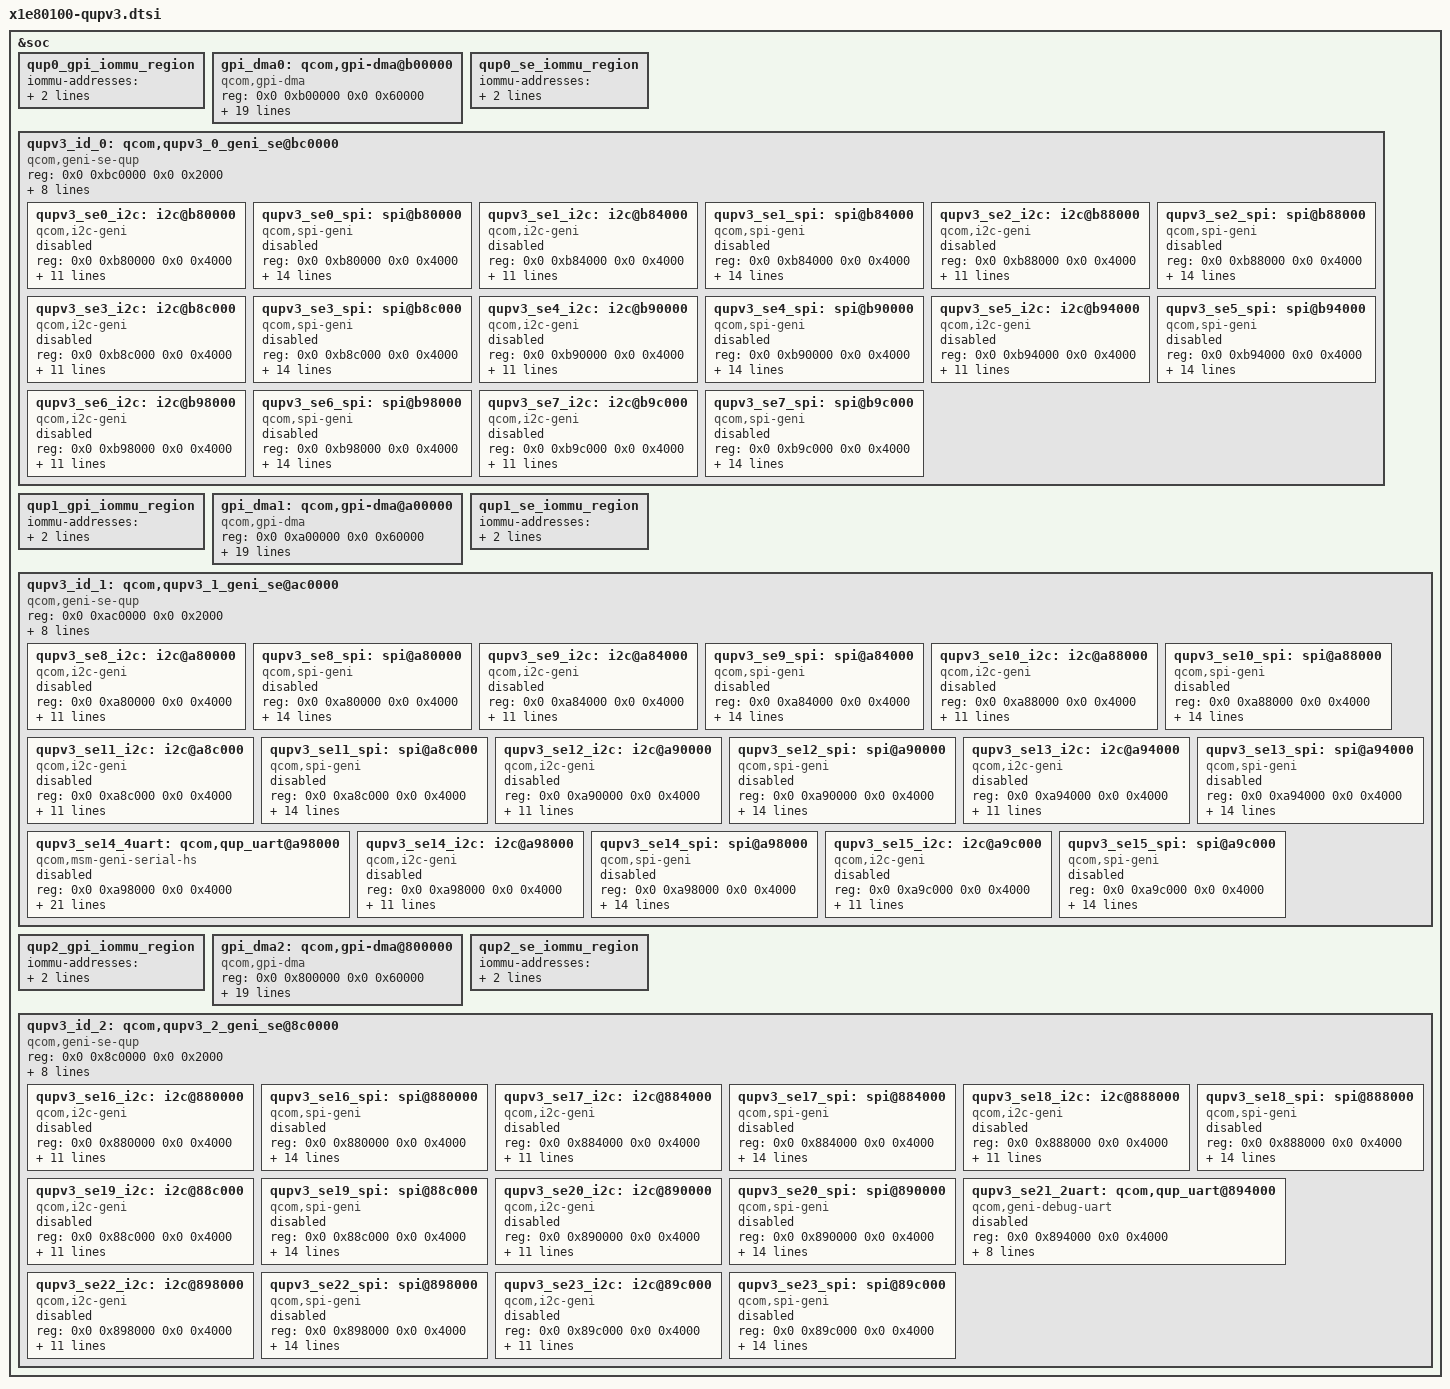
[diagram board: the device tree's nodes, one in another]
// SPDX-License-Identifier: BSD-3-Clause
/*
 * Copyright (c) Qualcomm Technologies, Inc. and/or its subsidiaries.
 */
#include <dt-bindings/clock/qcom,x1e80100-gcc.h>

&soc {
	qup0_gpi_iommu_region: qup0_gpi_iommu_region {
		iommu-addresses = <&gpi_dma0 0x0 0x0 0x0 0x100000>,
				  <&gpi_dma0 0x0 0x200000 0xffffffff 0xffe00000>;
	};

	gpi_dma0: qcom,gpi-dma@b00000 {
		compatible = "qcom,gpi-dma";
		#dma-cells = <5>;
		reg = <0x0 0xb00000 0x0 0x60000>;
		reg-names = "gpi-top";
		iommus = <&apps_smmu 0x0456 0x0>;
		qcom,max-num-gpii = <12>;
		interrupts = <GIC_SPI 588 IRQ_TYPE_LEVEL_HIGH>,
			     <GIC_SPI 589 IRQ_TYPE_LEVEL_HIGH>,
			     <GIC_SPI 590 IRQ_TYPE_LEVEL_HIGH>,
			     <GIC_SPI 591 IRQ_TYPE_LEVEL_HIGH>,
			     <GIC_SPI 592 IRQ_TYPE_LEVEL_HIGH>,
			     <GIC_SPI 593 IRQ_TYPE_LEVEL_HIGH>,
			     <GIC_SPI 594 IRQ_TYPE_LEVEL_HIGH>,
			     <GIC_SPI 595 IRQ_TYPE_LEVEL_HIGH>,
			     <GIC_SPI 596 IRQ_TYPE_LEVEL_HIGH>,
			     <GIC_SPI 597 IRQ_TYPE_LEVEL_HIGH>,
			     <GIC_SPI 598 IRQ_TYPE_LEVEL_HIGH>,
			     <GIC_SPI 599 IRQ_TYPE_LEVEL_HIGH>;
		qcom,gpii-mask = <0x3f>;
		qcom,ev-factor = <1>;
		memory-region = <&qup0_gpi_iommu_region>;
		qcom,gpi-ee-offset = <0x10000>;
		dma-coherent;
		status = "okay";
	};

	qup0_se_iommu_region: qup0_se_iommu_region {
		iommu-addresses = <&qupv3_id_0 0x0 0x0 0x0 0x40000000>,
				  <&qupv3_id_0 0x0 0x50000000 0xffffffff 0xb0000000>;
	};

	qupv3_id_0: qcom,qupv3_0_geni_se@bc0000 {
		compatible = "qcom,geni-se-qup";
		reg = <0x0 0xbc0000 0x0 0x2000>;
		clock-names = "m-ahb", "s-ahb";
		clocks = <&gcc GCC_QUPV3_WRAP_0_M_AHB_CLK>,
			 <&gcc GCC_QUPV3_WRAP_0_S_AHB_CLK>;
		iommus = <&apps_smmu 0x0443 0x0>;
		memory-region = <&qup0_se_iommu_region>;
		qcom,iommu-geometry = <0x0 0x40000000 0x0 0x10000000>;
		qcom,iommu-dma = "fastmap";
		dma-coherent;
		#address-cells = <2>;
		#size-cells = <2>;
		ranges;
		status = "okay";

		qupv3_se0_i2c: i2c@b80000 {
			compatible = "qcom,i2c-geni";
			reg = <0x0 0xb80000 0x0 0x4000>;
			interrupts = <GIC_SPI 373 IRQ_TYPE_LEVEL_HIGH>;
			clock-names = "se-clk";
			clocks = <&gcc GCC_QUPV3_WRAP0_S0_CLK>;
			interconnect-names = "qup-core", "qup-config", "qup-memory";
			interconnects = <&clk_virt MASTER_QUP_CORE_0 &clk_virt SLAVE_QUP_CORE_0>,
					<&gem_noc MASTER_APPSS_PROC &config_noc SLAVE_QUP_0>,
					<&aggre1_noc MASTER_QUP_0 &mc_virt SLAVE_EBI1>;
			pinctrl-names = "default", "sleep";
			pinctrl-0 = <&qupv3_se0_i2c_sda_active>, <&qupv3_se0_i2c_scl_active>;
			pinctrl-1 = <&qupv3_se0_i2c_sleep>;
			dmas = <&gpi_dma0 0 0 3 64 0>,
			       <&gpi_dma0 1 0 3 64 0>;
			dma-names = "tx", "rx";
			status = "disabled";
		};

		qupv3_se0_spi: spi@b80000 {
			compatible = "qcom,spi-geni";
			reg = <0x0 0xb80000 0x0 0x4000>;
			reg-names = "se_phys";
			interrupts = <GIC_SPI 373 IRQ_TYPE_LEVEL_HIGH>;
			clock-names = "se-clk";
			clocks = <&gcc GCC_QUPV3_WRAP0_S0_CLK>;
			interconnect-names = "qup-core", "qup-config", "qup-memory";
			interconnects = <&clk_virt MASTER_QUP_CORE_0 &clk_virt SLAVE_QUP_CORE_0>,
					<&gem_noc MASTER_APPSS_PROC &config_noc SLAVE_QUP_0>,
					<&aggre1_noc MASTER_QUP_0 &mc_virt SLAVE_EBI1>;
			pinctrl-names = "default", "sleep";
			pinctrl-0 = <&qupv3_se0_spi_mosi_active>, <&qupv3_se0_spi_miso_active>,
				    <&qupv3_se0_spi_clk_active>, <&qupv3_se0_spi_cs_active>;
			pinctrl-1 = <&qupv3_se0_spi_sleep>;
			dmas = <&gpi_dma0 0 0 1 64 0>,
				<&gpi_dma0 1 0 1 64 0>;
			dma-names = "tx", "rx";
			spi-max-frequency = <50000000>;
			status = "disabled";
		};

		qupv3_se1_i2c: i2c@b84000 {
			compatible = "qcom,i2c-geni";
			reg = <0x0 0xb84000 0x0 0x4000>;
			interrupts = <GIC_SPI 583 IRQ_TYPE_LEVEL_HIGH>;
			clock-names = "se-clk";
			clocks = <&gcc GCC_QUPV3_WRAP0_S1_CLK>;
			interconnect-names = "qup-core", "qup-config", "qup-memory";
			interconnects = <&clk_virt MASTER_QUP_CORE_0 &clk_virt SLAVE_QUP_CORE_0>,
					<&gem_noc MASTER_APPSS_PROC &config_noc SLAVE_QUP_0>,
					<&aggre1_noc MASTER_QUP_0 &mc_virt SLAVE_EBI1>;
			pinctrl-names = "default", "sleep";
			pinctrl-0 = <&qupv3_se1_i2c_sda_active>, <&qupv3_se1_i2c_scl_active>;
			pinctrl-1 = <&qupv3_se1_i2c_sleep>;
			dmas = <&gpi_dma0 0 1 3 64 0>,
			       <&gpi_dma0 1 1 3 64 0>;
			dma-names = "tx", "rx";
			status = "disabled";
		};

		qupv3_se1_spi: spi@b84000 {
			compatible = "qcom,spi-geni";
			reg = <0x0 0xb84000 0x0 0x4000>;
			reg-names = "se_phys";
			interrupts = <GIC_SPI 583 IRQ_TYPE_LEVEL_HIGH>;
			clock-names = "se-clk";
			clocks = <&gcc GCC_QUPV3_WRAP0_S1_CLK>;
			interconnect-names = "qup-core", "qup-config", "qup-memory";
			interconnects = <&clk_virt MASTER_QUP_CORE_0 &clk_virt SLAVE_QUP_CORE_0>,
					<&gem_noc MASTER_APPSS_PROC &config_noc SLAVE_QUP_0>,
					<&aggre1_noc MASTER_QUP_0 &mc_virt SLAVE_EBI1>;
			pinctrl-names = "default", "sleep";
			pinctrl-0 = <&qupv3_se1_spi_mosi_active>, <&qupv3_se1_spi_miso_active>,
				    <&qupv3_se1_spi_clk_active>, <&qupv3_se1_spi_cs_active>;
			pinctrl-1 = <&qupv3_se1_spi_sleep>;
			dmas = <&gpi_dma0 0 1 1 64 0>,
			       <&gpi_dma0 1 1 1 64 0>;
			dma-names = "tx", "rx";
			spi-max-frequency = <50000000>;
			status = "disabled";
		};

		qupv3_se2_i2c: i2c@b88000 {
			compatible = "qcom,i2c-geni";
			reg = <0x0 0xb88000 0x0 0x4000>;
			interrupts = <GIC_SPI 584 IRQ_TYPE_LEVEL_HIGH>;
			clock-names = "se-clk";
			clocks = <&gcc GCC_QUPV3_WRAP0_S2_CLK>;
			interconnect-names = "qup-core", "qup-config", "qup-memory";
			interconnects = <&clk_virt MASTER_QUP_CORE_0 &clk_virt SLAVE_QUP_CORE_0>,
					<&gem_noc MASTER_APPSS_PROC &config_noc SLAVE_QUP_0>,
					<&aggre1_noc MASTER_QUP_0 &mc_virt SLAVE_EBI1>;
			pinctrl-names = "default", "sleep";
			pinctrl-0 = <&qupv3_se2_i2c_sda_active>, <&qupv3_se2_i2c_scl_active>;
			pinctrl-1 = <&qupv3_se2_i2c_sleep>;
			dmas = <&gpi_dma0 0 2 3 64 0>,
			       <&gpi_dma0 1 2 3 64 0>;
			dma-names = "tx", "rx";
			status = "disabled";
		};

		qupv3_se2_spi: spi@b88000 {
			compatible = "qcom,spi-geni";
			reg = <0x0 0xb88000 0x0 0x4000>;
			reg-names = "se_phys";
			interrupts = <GIC_SPI 584 IRQ_TYPE_LEVEL_HIGH>;
			clock-names = "se-clk";
			clocks = <&gcc GCC_QUPV3_WRAP0_S2_CLK>;
			interconnect-names = "qup-core", "qup-config", "qup-memory";
			interconnects = <&clk_virt MASTER_QUP_CORE_0 &clk_virt SLAVE_QUP_CORE_0>,
					<&gem_noc MASTER_APPSS_PROC &config_noc SLAVE_QUP_0>,
					<&aggre1_noc MASTER_QUP_0 &mc_virt SLAVE_EBI1>;
			pinctrl-names = "default", "sleep";
			pinctrl-0 = <&qupv3_se2_spi_mosi_active>, <&qupv3_se2_spi_miso_active>,
				    <&qupv3_se2_spi_clk_active>, <&qupv3_se2_spi_cs_active>;
			pinctrl-1 = <&qupv3_se2_spi_sleep>;
			dmas = <&gpi_dma0 0 2 1 64 0>,
			       <&gpi_dma0 1 2 1 64 0>;
			dma-names = "tx", "rx";
			spi-max-frequency = <50000000>;
			status = "disabled";
		};

		qupv3_se3_i2c: i2c@b8c000 {
			compatible = "qcom,i2c-geni";
			reg = <0x0 0xb8c000 0x0 0x4000>;
			interrupts = <GIC_SPI 585 IRQ_TYPE_LEVEL_HIGH>;
			clock-names = "se-clk";
			clocks = <&gcc GCC_QUPV3_WRAP0_S3_CLK>;
			interconnect-names = "qup-core", "qup-config", "qup-memory";
			interconnects = <&clk_virt MASTER_QUP_CORE_0 &clk_virt SLAVE_QUP_CORE_0>,
					<&gem_noc MASTER_APPSS_PROC &config_noc SLAVE_QUP_0>,
					<&aggre1_noc MASTER_QUP_0 &mc_virt SLAVE_EBI1>;
			pinctrl-names = "default", "sleep";
			pinctrl-0 = <&qupv3_se3_i2c_sda_active>, <&qupv3_se3_i2c_scl_active>;
			pinctrl-1 = <&qupv3_se3_i2c_sleep>;
			dmas = <&gpi_dma0 0 3 3 64 0>,
			       <&gpi_dma0 1 3 3 64 0>;
			dma-names = "tx", "rx";
			status = "disabled";
		};

		qupv3_se3_spi: spi@b8c000 {
			compatible = "qcom,spi-geni";
			reg = <0x0 0xb8c000 0x0 0x4000>;
			reg-names = "se_phys";
			interrupts = <GIC_SPI 585 IRQ_TYPE_LEVEL_HIGH>;
			clock-names = "se-clk";
			clocks = <&gcc GCC_QUPV3_WRAP0_S3_CLK>;
			interconnect-names = "qup-core", "qup-config", "qup-memory";
			interconnects = <&clk_virt MASTER_QUP_CORE_0 &clk_virt SLAVE_QUP_CORE_0>,
					<&gem_noc MASTER_APPSS_PROC &config_noc SLAVE_QUP_0>,
					<&aggre1_noc MASTER_QUP_0 &mc_virt SLAVE_EBI1>;
			pinctrl-names = "default", "sleep";
			pinctrl-0 = <&qupv3_se3_spi_mosi_active>, <&qupv3_se3_spi_miso_active>,
				    <&qupv3_se3_spi_clk_active>, <&qupv3_se3_spi_cs_active>;
			pinctrl-1 = <&qupv3_se3_spi_sleep>;
			dmas = <&gpi_dma0 0 3 1 64 0>,
			       <&gpi_dma0 1 3 1 64 0>;
			dma-names = "tx", "rx";
			spi-max-frequency = <50000000>;
			status = "disabled";
		};

		qupv3_se4_i2c: i2c@b90000 {
			compatible = "qcom,i2c-geni";
			reg = <0x0 0xb90000 0x0 0x4000>;
			interrupts = <GIC_SPI 586 IRQ_TYPE_LEVEL_HIGH>;
			clock-names = "se-clk";
			clocks = <&gcc GCC_QUPV3_WRAP0_S4_CLK>;
			interconnect-names = "qup-core", "qup-config", "qup-memory";
			interconnects = <&clk_virt MASTER_QUP_CORE_0 &clk_virt SLAVE_QUP_CORE_0>,
					<&gem_noc MASTER_APPSS_PROC &config_noc SLAVE_QUP_0>,
					<&aggre1_noc MASTER_QUP_0 &mc_virt SLAVE_EBI1>;
			pinctrl-names = "default", "sleep";
			pinctrl-0 = <&qupv3_se4_i2c_sda_active>, <&qupv3_se4_i2c_scl_active>;
			pinctrl-1 = <&qupv3_se4_i2c_sleep>;
			dmas = <&gpi_dma0 0 4 3 64 0>,
			       <&gpi_dma0 1 4 3 64 0>;
			dma-names = "tx", "rx";
			status = "disabled";
		};

		qupv3_se4_spi: spi@b90000 {
			compatible = "qcom,spi-geni";
			reg = <0x0 0xb90000 0x0 0x4000>;
			reg-names = "se_phys";
			interrupts = <GIC_SPI 586 IRQ_TYPE_LEVEL_HIGH>;
			clock-names = "se-clk";
			clocks = <&gcc GCC_QUPV3_WRAP0_S4_CLK>;
			interconnect-names = "qup-core", "qup-config", "qup-memory";
			interconnects = <&clk_virt MASTER_QUP_CORE_0 &clk_virt SLAVE_QUP_CORE_0>,
					<&gem_noc MASTER_APPSS_PROC &config_noc SLAVE_QUP_0>,
					<&aggre1_noc MASTER_QUP_0 &mc_virt SLAVE_EBI1>;
			pinctrl-names = "default", "sleep";
			pinctrl-0 = <&qupv3_se4_spi_mosi_active>, <&qupv3_se4_spi_miso_active>,
				    <&qupv3_se4_spi_clk_active>, <&qupv3_se4_spi_cs_active>;
			pinctrl-1 = <&qupv3_se4_spi_sleep>;
			dmas = <&gpi_dma0 0 4 1 64 0>,
			       <&gpi_dma0 1 4 1 64 0>;
			dma-names = "tx", "rx";
			spi-max-frequency = <50000000>;
			status = "disabled";
		};

		qupv3_se5_i2c: i2c@b94000 {
			compatible = "qcom,i2c-geni";
			reg = <0x0 0xb94000 0x0 0x4000>;
			interrupts = <GIC_SPI 587 IRQ_TYPE_LEVEL_HIGH>;
			clock-names = "se-clk";
			clocks = <&gcc GCC_QUPV3_WRAP0_S5_CLK>;
			interconnect-names = "qup-core", "qup-config", "qup-memory";
			interconnects = <&clk_virt MASTER_QUP_CORE_0 &clk_virt SLAVE_QUP_CORE_0>,
					<&gem_noc MASTER_APPSS_PROC &config_noc SLAVE_QUP_0>,
					<&aggre1_noc MASTER_QUP_0 &mc_virt SLAVE_EBI1>;
			pinctrl-names = "default", "sleep";
			pinctrl-0 = <&qupv3_se5_i2c_sda_active>, <&qupv3_se5_i2c_scl_active>;
			pinctrl-1 = <&qupv3_se5_i2c_sleep>;
			dmas = <&gpi_dma0 0 5 3 64 0>,
			       <&gpi_dma0 1 5 3 64 0>;
			dma-names = "tx", "rx";
			status = "disabled";
		};

		qupv3_se5_spi: spi@b94000 {
			compatible = "qcom,spi-geni";
			reg = <0x0 0xb94000 0x0 0x4000>;
			reg-names = "se_phys";
			interrupts = <GIC_SPI 587 IRQ_TYPE_LEVEL_HIGH>;
			clock-names = "se-clk";
			clocks = <&gcc GCC_QUPV3_WRAP0_S5_CLK>;
			interconnect-names = "qup-core", "qup-config", "qup-memory";
			interconnects = <&clk_virt MASTER_QUP_CORE_0 &clk_virt SLAVE_QUP_CORE_0>,
					<&gem_noc MASTER_APPSS_PROC &config_noc SLAVE_QUP_0>,
					<&aggre1_noc MASTER_QUP_0 &mc_virt SLAVE_EBI1>;
			pinctrl-names = "default", "sleep";
			pinctrl-0 = <&qupv3_se5_spi_mosi_active>, <&qupv3_se5_spi_miso_active>,
				    <&qupv3_se5_spi_clk_active>, <&qupv3_se5_spi_cs_active>;
			pinctrl-1 = <&qupv3_se5_spi_sleep>;
			dmas = <&gpi_dma0 0 5 1 64 0>,
			       <&gpi_dma0 1 5 1 64 0>;
			dma-names = "tx", "rx";
			spi-max-frequency = <50000000>;
			status = "disabled";
		};

		qupv3_se6_i2c: i2c@b98000 {
			compatible = "qcom,i2c-geni";
			reg = <0x0 0xb98000 0x0 0x4000>;
			interrupts = <GIC_SPI 461 IRQ_TYPE_LEVEL_HIGH>;
			clock-names = "se-clk";
			clocks = <&gcc GCC_QUPV3_WRAP0_S6_CLK>;
			interconnect-names = "qup-core", "qup-config", "qup-memory";
			interconnects = <&clk_virt MASTER_QUP_CORE_0 &clk_virt SLAVE_QUP_CORE_0>,
					<&gem_noc MASTER_APPSS_PROC &config_noc SLAVE_QUP_0>,
					<&aggre1_noc MASTER_QUP_0 &mc_virt SLAVE_EBI1>;
			pinctrl-names = "default", "sleep";
			pinctrl-0 = <&qupv3_se6_i2c_sda_active>, <&qupv3_se6_i2c_scl_active>;
			pinctrl-1 = <&qupv3_se6_i2c_sleep>;
			dmas = <&gpi_dma0 0 6 3 64 0>,
			       <&gpi_dma0 1 6 3 64 0>;
			dma-names = "tx", "rx";
			status = "disabled";
		};

		qupv3_se6_spi: spi@b98000 {
			compatible = "qcom,spi-geni";
			reg = <0x0 0xb98000 0x0 0x4000>;
			reg-names = "se_phys";
			interrupts = <GIC_SPI 461 IRQ_TYPE_LEVEL_HIGH>;
			clock-names = "se-clk";
			clocks = <&gcc GCC_QUPV3_WRAP0_S6_CLK>;
			interconnect-names = "qup-core", "qup-config", "qup-memory";
			interconnects = <&clk_virt MASTER_QUP_CORE_0 &clk_virt SLAVE_QUP_CORE_0>,
					<&gem_noc MASTER_APPSS_PROC &config_noc SLAVE_QUP_0>,
					<&aggre1_noc MASTER_QUP_0 &mc_virt SLAVE_EBI1>;
			pinctrl-names = "default", "sleep";
			pinctrl-0 = <&qupv3_se6_spi_mosi_active>, <&qupv3_se6_spi_miso_active>,
				    <&qupv3_se6_spi_clk_active>, <&qupv3_se6_spi_cs_active>;
			pinctrl-1 = <&qupv3_se6_spi_sleep>;
			dmas = <&gpi_dma0 0 6 1 64 0>,
			       <&gpi_dma0 1 6 1 64 0>;
			dma-names = "tx", "rx";
			spi-max-frequency = <50000000>;
			status = "disabled";
		};

		qupv3_se7_i2c: i2c@b9c000 {
			compatible = "qcom,i2c-geni";
			reg = <0x0 0xb9c000 0x0 0x4000>;
			interrupts = <GIC_SPI 462 IRQ_TYPE_LEVEL_HIGH>;
			clock-names = "se-clk";
			clocks = <&gcc GCC_QUPV3_WRAP0_S7_CLK>;
			interconnect-names = "qup-core", "qup-config", "qup-memory";
			interconnects = <&clk_virt MASTER_QUP_CORE_0 &clk_virt SLAVE_QUP_CORE_0>,
					<&gem_noc MASTER_APPSS_PROC &config_noc SLAVE_QUP_0>,
					<&aggre1_noc MASTER_QUP_0 &mc_virt SLAVE_EBI1>;
			pinctrl-names = "default", "sleep";
			pinctrl-0 = <&qupv3_se7_i2c_sda_active>, <&qupv3_se7_i2c_scl_active>;
			pinctrl-1 = <&qupv3_se7_i2c_sleep>;
			dmas = <&gpi_dma0 0 7 3 64 0>,
			       <&gpi_dma0 1 7 3 64 0>;
			dma-names = "tx", "rx";
			status = "disabled";
		};

		qupv3_se7_spi: spi@b9c000 {
			compatible = "qcom,spi-geni";
			reg = <0x0 0xb9c000 0x0 0x4000>;
			reg-names = "se_phys";
			interrupts = <GIC_SPI 462 IRQ_TYPE_LEVEL_HIGH>;
			clock-names = "se-clk";
			clocks = <&gcc GCC_QUPV3_WRAP0_S7_CLK>;
			interconnect-names = "qup-core", "qup-config", "qup-memory";
			interconnects = <&clk_virt MASTER_QUP_CORE_0 &clk_virt SLAVE_QUP_CORE_0>,
					<&gem_noc MASTER_APPSS_PROC &config_noc SLAVE_QUP_0>,
					<&aggre1_noc MASTER_QUP_0 &mc_virt SLAVE_EBI1>;
			pinctrl-names = "default", "sleep";
			pinctrl-0 = <&qupv3_se7_spi_mosi_active>, <&qupv3_se7_spi_miso_active>,
				    <&qupv3_se7_spi_clk_active>, <&qupv3_se7_spi_cs_active>;
			pinctrl-1 = <&qupv3_se7_spi_sleep>;
			dmas = <&gpi_dma0 0 7 1 64 0>,
			       <&gpi_dma0 1 7 1 64 0>;
			dma-names = "tx", "rx";
			spi-max-frequency = <50000000>;
			status = "disabled";
		};
	};

	qup1_gpi_iommu_region: qup1_gpi_iommu_region {
		iommu-addresses = <&gpi_dma1 0x0 0x0 0x0 0x100000>,
				  <&gpi_dma1 0x0 0x200000 0xffffffff 0xffe00000>;
	};

	gpi_dma1: qcom,gpi-dma@a00000 {
		compatible = "qcom,gpi-dma";
		#dma-cells = <5>;
		reg = <0x0 0xa00000 0x0 0x60000>;
		reg-names = "gpi-top";
		iommus = <&apps_smmu 0X0136 0x0>;
		qcom,max-num-gpii = <12>;
		interrupts = <GIC_SPI 776 IRQ_TYPE_LEVEL_HIGH>,
			     <GIC_SPI 777 IRQ_TYPE_LEVEL_HIGH>,
			     <GIC_SPI 778 IRQ_TYPE_LEVEL_HIGH>,
			     <GIC_SPI 779 IRQ_TYPE_LEVEL_HIGH>,
			     <GIC_SPI 780 IRQ_TYPE_LEVEL_HIGH>,
			     <GIC_SPI 781 IRQ_TYPE_LEVEL_HIGH>,
			     <GIC_SPI 782 IRQ_TYPE_LEVEL_HIGH>,
			     <GIC_SPI 783 IRQ_TYPE_LEVEL_HIGH>,
			     <GIC_SPI 784 IRQ_TYPE_LEVEL_HIGH>,
			     <GIC_SPI 785 IRQ_TYPE_LEVEL_HIGH>,
			     <GIC_SPI 786 IRQ_TYPE_LEVEL_HIGH>,
			     <GIC_SPI 787 IRQ_TYPE_LEVEL_HIGH>;
		qcom,gpii-mask = <0x3f>;
		qcom,ev-factor = <1>;
		memory-region = <&qup1_gpi_iommu_region>;
		qcom,gpi-ee-offset = <0x10000>;
		dma-coherent;
		status = "okay";
	};

	qup1_se_iommu_region: qup1_se_iommu_region {
		iommu-addresses = <&qupv3_id_1 0x0 0x0 0x0 0x40000000>,
				  <&qupv3_id_1 0x0 0x50000000 0xffffffff 0xb0000000>;
	};

	qupv3_id_1: qcom,qupv3_1_geni_se@ac0000 {
		compatible = "qcom,geni-se-qup";
		reg = <0x0 0xac0000 0x0 0x2000>;
		clock-names = "m-ahb", "s-ahb";
		clocks = <&gcc GCC_QUPV3_WRAP_1_M_AHB_CLK>,
			 <&gcc GCC_QUPV3_WRAP_1_S_AHB_CLK>;
		iommus = <&apps_smmu 0x0123 0x0>;
		memory-region = <&qup1_se_iommu_region>;
		qcom,iommu-geometry = <0x0 0x40000000 0x0 0x10000000>;
		qcom,iommu-dma = "fastmap";
		dma-coherent;
		#address-cells = <2>;
		#size-cells = <2>;
		ranges;
		status = "okay";

		qupv3_se8_i2c: i2c@a80000 {
			compatible = "qcom,i2c-geni";
			reg = <0x0 0xa80000 0x0 0x4000>;
			interrupts = <GIC_SPI 800 IRQ_TYPE_LEVEL_HIGH>;
			clock-names = "se-clk";
			clocks = <&gcc GCC_QUPV3_WRAP1_S0_CLK>;
			interconnect-names = "qup-core", "qup-config", "qup-memory";
			interconnects = <&clk_virt MASTER_QUP_CORE_1 &clk_virt SLAVE_QUP_CORE_1>,
					<&gem_noc MASTER_APPSS_PROC &config_noc SLAVE_QUP_1>,
					<&aggre1_noc MASTER_QUP_1 &mc_virt SLAVE_EBI1>;
			pinctrl-names = "default", "sleep";
			pinctrl-0 = <&qupv3_se8_i2c_sda_active>, <&qupv3_se8_i2c_scl_active>;
			pinctrl-1 = <&qupv3_se8_i2c_sleep>;
			dmas = <&gpi_dma1 0 0 3 64 0>,
			       <&gpi_dma1 1 0 3 64 0>;
			dma-names = "tx", "rx";
			status = "disabled";
		};

		qupv3_se8_spi: spi@a80000 {
			compatible = "qcom,spi-geni";
			reg = <0x0 0xa80000 0x0 0x4000>;
			reg-names = "se_phys";
			interrupts = <GIC_SPI 800 IRQ_TYPE_LEVEL_HIGH>;
			clock-names = "se-clk";
			clocks = <&gcc GCC_QUPV3_WRAP1_S0_CLK>;
			interconnect-names = "qup-core", "qup-config", "qup-memory";
			interconnects = <&clk_virt MASTER_QUP_CORE_1 &clk_virt SLAVE_QUP_CORE_1>,
					<&gem_noc MASTER_APPSS_PROC &config_noc SLAVE_QUP_1>,
					<&aggre1_noc MASTER_QUP_1 &mc_virt SLAVE_EBI1>;
			pinctrl-names = "default", "sleep";
			pinctrl-0 = <&qupv3_se8_spi_mosi_active>, <&qupv3_se8_spi_miso_active>,
				    <&qupv3_se8_spi_clk_active>, <&qupv3_se8_spi_cs_active>;
			pinctrl-1 = <&qupv3_se8_spi_sleep>;
			dmas = <&gpi_dma1 0 0 1 64 0>,
			       <&gpi_dma1 1 0 1 64 0>;
			dma-names = "tx", "rx";
			spi-max-frequency = <50000000>;
			status = "disabled";
		};

		qupv3_se9_i2c: i2c@a84000 {
			compatible = "qcom,i2c-geni";
			reg = <0x0 0xa84000 0x0 0x4000>;
			interrupts = <GIC_SPI 801 IRQ_TYPE_LEVEL_HIGH>;
			clock-names = "se-clk";
			clocks = <&gcc GCC_QUPV3_WRAP1_S1_CLK>;
			interconnect-names = "qup-core", "qup-config", "qup-memory";
			interconnects = <&clk_virt MASTER_QUP_CORE_1 &clk_virt SLAVE_QUP_CORE_1>,
					<&gem_noc MASTER_APPSS_PROC &config_noc SLAVE_QUP_1>,
					<&aggre1_noc MASTER_QUP_1 &mc_virt SLAVE_EBI1>;
			pinctrl-names = "default", "sleep";
			pinctrl-0 = <&qupv3_se9_i2c_sda_active>, <&qupv3_se9_i2c_scl_active>;
			pinctrl-1 = <&qupv3_se9_i2c_sleep>;
			dmas = <&gpi_dma1 0 1 3 64 0>,
			       <&gpi_dma1 1 1 3 64 0>;
			dma-names = "tx", "rx";
			status = "disabled";
		};

		qupv3_se9_spi: spi@a84000 {
			compatible = "qcom,spi-geni";
			reg = <0x0 0xa84000 0x0 0x4000>;
			reg-names = "se_phys";
			interrupts = <GIC_SPI 801 IRQ_TYPE_LEVEL_HIGH>;
			clock-names = "se-clk";
			clocks = <&gcc GCC_QUPV3_WRAP1_S1_CLK>;
			interconnect-names = "qup-core", "qup-config", "qup-memory";
			interconnects = <&clk_virt MASTER_QUP_CORE_1 &clk_virt SLAVE_QUP_CORE_1>,
					<&gem_noc MASTER_APPSS_PROC &config_noc SLAVE_QUP_1>,
					<&aggre1_noc MASTER_QUP_1 &mc_virt SLAVE_EBI1>;
			pinctrl-names = "default", "sleep";
			pinctrl-0 = <&qupv3_se9_spi_mosi_active>, <&qupv3_se9_spi_miso_active>,
				    <&qupv3_se9_spi_clk_active>, <&qupv3_se9_spi_cs_active>;
			pinctrl-1 = <&qupv3_se9_spi_sleep>;
			dmas = <&gpi_dma1 0 1 1 64 0>,
			       <&gpi_dma1 1 1 1 64 0>;
			dma-names = "tx", "rx";
			spi-max-frequency = <50000000>;
			status = "disabled";
		};

		qupv3_se10_i2c: i2c@a88000 {
			compatible = "qcom,i2c-geni";
			reg = <0x0 0xa88000 0x0 0x4000>;
			interrupts = <GIC_SPI 802 IRQ_TYPE_LEVEL_HIGH>;
			clock-names = "se-clk";
			clocks = <&gcc GCC_QUPV3_WRAP1_S2_CLK>;
			interconnect-names = "qup-core", "qup-config", "qup-memory";
			interconnects = <&clk_virt MASTER_QUP_CORE_1 &clk_virt SLAVE_QUP_CORE_1>,
					<&gem_noc MASTER_APPSS_PROC &config_noc SLAVE_QUP_1>,
					<&aggre1_noc MASTER_QUP_1 &mc_virt SLAVE_EBI1>;
			pinctrl-names = "default", "sleep";
			pinctrl-0 = <&qupv3_se10_i2c_sda_active>, <&qupv3_se10_i2c_scl_active>;
			pinctrl-1 = <&qupv3_se10_i2c_sleep>;
			dmas = <&gpi_dma1 0 2 3 64 0>,
			       <&gpi_dma1 1 2 3 64 0>;
			dma-names = "tx", "rx";
			status = "disabled";
		};

		qupv3_se10_spi: spi@a88000 {
			compatible = "qcom,spi-geni";
			reg = <0x0 0xa88000 0x0 0x4000>;
			reg-names = "se_phys";
			interrupts = <GIC_SPI 802 IRQ_TYPE_LEVEL_HIGH>;
			clock-names = "se-clk";
			clocks = <&gcc GCC_QUPV3_WRAP1_S2_CLK>;
			interconnect-names = "qup-core", "qup-config", "qup-memory";
			interconnects = <&clk_virt MASTER_QUP_CORE_1 &clk_virt SLAVE_QUP_CORE_1>,
					<&gem_noc MASTER_APPSS_PROC &config_noc SLAVE_QUP_1>,
					<&aggre1_noc MASTER_QUP_1 &mc_virt SLAVE_EBI1>;
			pinctrl-names = "default", "sleep";
			pinctrl-0 = <&qupv3_se10_spi_mosi_active>, <&qupv3_se10_spi_miso_active>,
				    <&qupv3_se10_spi_clk_active>, <&qupv3_se10_spi_cs_active>;
			pinctrl-1 = <&qupv3_se10_spi_sleep>;
			dmas = <&gpi_dma1 0 2 1 64 0>,
			       <&gpi_dma1 1 2 1 64 0>;
			dma-names = "tx", "rx";
			spi-max-frequency = <50000000>;
			status = "disabled";
		};

		qupv3_se11_i2c: i2c@a8c000 {
			compatible = "qcom,i2c-geni";
			reg = <0x0 0xa8c000 0x0 0x4000>;
			interrupts = <GIC_SPI 803 IRQ_TYPE_LEVEL_HIGH>;
			clock-names = "se-clk";
			clocks = <&gcc GCC_QUPV3_WRAP1_S3_CLK>;
			interconnect-names = "qup-core", "qup-config", "qup-memory";
			interconnects = <&clk_virt MASTER_QUP_CORE_1 &clk_virt SLAVE_QUP_CORE_1>,
					<&gem_noc MASTER_APPSS_PROC &config_noc SLAVE_QUP_1>,
					<&aggre1_noc MASTER_QUP_1 &mc_virt SLAVE_EBI1>;
			pinctrl-names = "default", "sleep";
			pinctrl-0 = <&qupv3_se11_i2c_sda_active>, <&qupv3_se11_i2c_scl_active>;
			pinctrl-1 = <&qupv3_se11_i2c_sleep>;
			dmas = <&gpi_dma1 0 3 3 64 0>,
			       <&gpi_dma1 1 3 3 64 0>;
			dma-names = "tx", "rx";
			status = "disabled";
		};

		qupv3_se11_spi: spi@a8c000 {
			compatible = "qcom,spi-geni";
			reg = <0x0 0xa8c000 0x0 0x4000>;
			reg-names = "se_phys";
			interrupts = <GIC_SPI 803 IRQ_TYPE_LEVEL_HIGH>;
			clock-names = "se-clk";
			clocks = <&gcc GCC_QUPV3_WRAP1_S3_CLK>;
			interconnect-names = "qup-core", "qup-config", "qup-memory";
			interconnects = <&clk_virt MASTER_QUP_CORE_1 &clk_virt SLAVE_QUP_CORE_1>,
					<&gem_noc MASTER_APPSS_PROC &config_noc SLAVE_QUP_1>,
					<&aggre1_noc MASTER_QUP_1 &mc_virt SLAVE_EBI1>;
			pinctrl-names = "default", "sleep";
			pinctrl-0 = <&qupv3_se11_spi_mosi_active>, <&qupv3_se11_spi_miso_active>,
				    <&qupv3_se11_spi_clk_active>, <&qupv3_se11_spi_cs_active>;
			pinctrl-1 = <&qupv3_se11_spi_sleep>;
			dmas = <&gpi_dma1 0 3 1 64 0>,
			       <&gpi_dma1 1 3 1 64 0>;
			dma-names = "tx", "rx";
			spi-max-frequency = <50000000>;
			status = "disabled";
		};

		qupv3_se12_i2c: i2c@a90000 {
			compatible = "qcom,i2c-geni";
			reg = <0x0 0xa90000 0x0 0x4000>;
			interrupts = <GIC_SPI 804 IRQ_TYPE_LEVEL_HIGH>;
			clock-names = "se-clk";
			clocks = <&gcc GCC_QUPV3_WRAP1_S4_CLK>;
			interconnect-names = "qup-core", "qup-config", "qup-memory";
			interconnects = <&clk_virt MASTER_QUP_CORE_1 &clk_virt SLAVE_QUP_CORE_1>,
					<&gem_noc MASTER_APPSS_PROC &config_noc SLAVE_QUP_1>,
					<&aggre1_noc MASTER_QUP_1 &mc_virt SLAVE_EBI1>;
			pinctrl-names = "default", "sleep";
			pinctrl-0 = <&qupv3_se12_i2c_sda_active>, <&qupv3_se12_i2c_scl_active>;
			pinctrl-1 = <&qupv3_se12_i2c_sleep>;
			dmas = <&gpi_dma1 0 4 3 64 0>,
			       <&gpi_dma1 1 4 3 64 0>;
			dma-names = "tx", "rx";
			status = "disabled";
		};

		qupv3_se12_spi: spi@a90000 {
			compatible = "qcom,spi-geni";
			reg = <0x0 0xa90000 0x0 0x4000>;
			reg-names = "se_phys";
			interrupts = <GIC_SPI 804 IRQ_TYPE_LEVEL_HIGH>;
			clock-names = "se-clk";
			clocks = <&gcc GCC_QUPV3_WRAP1_S4_CLK>;
			interconnect-names = "qup-core", "qup-config", "qup-memory";
			interconnects = <&clk_virt MASTER_QUP_CORE_1 &clk_virt SLAVE_QUP_CORE_1>,
					<&gem_noc MASTER_APPSS_PROC &config_noc SLAVE_QUP_1>,
					<&aggre1_noc MASTER_QUP_1 &mc_virt SLAVE_EBI1>;
			pinctrl-names = "default", "sleep";
			pinctrl-0 = <&qupv3_se12_spi_mosi_active>, <&qupv3_se12_spi_miso_active>,
				    <&qupv3_se12_spi_clk_active>, <&qupv3_se12_spi_cs_active>;
			pinctrl-1 = <&qupv3_se12_spi_sleep>;
			dmas = <&gpi_dma1 0 4 1 64 0>,
			       <&gpi_dma1 1 4 1 64 0>;
			dma-names = "tx", "rx";
			spi-max-frequency = <50000000>;
			status = "disabled";
		};

		qupv3_se13_i2c: i2c@a94000 {
			compatible = "qcom,i2c-geni";
			reg = <0x0 0xa94000 0x0 0x4000>;
			interrupts = <GIC_SPI 805 IRQ_TYPE_LEVEL_HIGH>;
			clock-names = "se-clk";
			clocks = <&gcc GCC_QUPV3_WRAP1_S5_CLK>;
			interconnect-names = "qup-core", "qup-config", "qup-memory";
			interconnects = <&clk_virt MASTER_QUP_CORE_1 &clk_virt SLAVE_QUP_CORE_1>,
					<&gem_noc MASTER_APPSS_PROC &config_noc SLAVE_QUP_1>,
					<&aggre1_noc MASTER_QUP_1 &mc_virt SLAVE_EBI1>;
			pinctrl-names = "default", "sleep";
			pinctrl-0 = <&qupv3_se13_i2c_sda_active>, <&qupv3_se13_i2c_scl_active>;
			pinctrl-1 = <&qupv3_se13_i2c_sleep>;
			dmas = <&gpi_dma1 0 5 3 64 0>,
			       <&gpi_dma1 1 5 3 64 0>;
			dma-names = "tx", "rx";
			status = "disabled";
		};

		qupv3_se13_spi: spi@a94000 {
			compatible = "qcom,spi-geni";
			reg = <0x0 0xa94000 0x0 0x4000>;
			reg-names = "se_phys";
			interrupts = <GIC_SPI 805 IRQ_TYPE_LEVEL_HIGH>;
			clock-names = "se-clk";
			clocks = <&gcc GCC_QUPV3_WRAP1_S5_CLK>;
			interconnect-names = "qup-core", "qup-config", "qup-memory";
			interconnects = <&clk_virt MASTER_QUP_CORE_1 &clk_virt SLAVE_QUP_CORE_1>,
					<&gem_noc MASTER_APPSS_PROC &config_noc SLAVE_QUP_1>,
					<&aggre1_noc MASTER_QUP_1 &mc_virt SLAVE_EBI1>;
			pinctrl-names = "default", "sleep";
			pinctrl-0 = <&qupv3_se13_spi_mosi_active>, <&qupv3_se13_spi_miso_active>,
				    <&qupv3_se13_spi_clk_active>, <&qupv3_se13_spi_cs_active>;
			pinctrl-1 = <&qupv3_se13_spi_sleep>;
			dmas = <&gpi_dma1 0 5 1 64 0>,
			       <&gpi_dma1 1 5 1 64 0>;
			dma-names = "tx", "rx";
			spi-max-frequency = <50000000>;
			status = "disabled";
		};

		qupv3_se14_4uart: qcom,qup_uart@a98000 {
			compatible = "qcom,msm-geni-serial-hs";
			reg = <0x0 0xa98000 0x0 0x4000>;
			reg-names = "se_phys";
			interrupts-extended = <&intc GIC_SPI 806 IRQ_TYPE_LEVEL_HIGH>,
					      <&tlmm 59 IRQ_TYPE_LEVEL_HIGH>;
			clock-names = "se-clk";
			clocks = <&gcc GCC_QUPV3_WRAP1_S6_CLK>;
			interconnect-names = "qup-core", "qup-config", "qup-memory";
			interconnects = <&clk_virt MASTER_QUP_CORE_1 &clk_virt SLAVE_QUP_CORE_1>,
					<&gem_noc MASTER_APPSS_PROC &config_noc SLAVE_QUP_1>,
					<&aggre1_noc MASTER_QUP_1 &mc_virt SLAVE_EBI1>;
			pinctrl-names = "default", "active", "sleep", "shutdown";
			pinctrl-0 = <&qupv3_se14_default_cts>, <&qupv3_se14_default_rts>,
				    <&qupv3_se14_default_tx>, <&qupv3_se14_default_rx>;
			pinctrl-1 = <&qupv3_se14_cts>, <&qupv3_se14_rts>,
				    <&qupv3_se14_tx>, <&qupv3_se14_rx_active>;
			pinctrl-2 = <&qupv3_se14_cts>, <&qupv3_se14_rts>,
				    <&qupv3_se14_tx>, <&qupv3_se14_rx_wake>;
			pinctrl-3 = <&qupv3_se14_default_cts>, <&qupv3_se14_default_rts>,
				    <&qupv3_se14_default_tx>, <&qupv3_se14_default_rx>;
			qcom,wakeup-byte = <0xFD>;
			qcom,suspend-ignore-children;
			status = "disabled";
		};

		qupv3_se14_i2c: i2c@a98000 {
			compatible = "qcom,i2c-geni";
			reg = <0x0 0xa98000 0x0 0x4000>;
			interrupts = <GIC_SPI 806 IRQ_TYPE_LEVEL_HIGH>;
			clock-names = "se-clk";
			clocks = <&gcc GCC_QUPV3_WRAP1_S6_CLK>;
			interconnect-names = "qup-core", "qup-config", "qup-memory";
			interconnects = <&clk_virt MASTER_QUP_CORE_1 &clk_virt SLAVE_QUP_CORE_1>,
					<&gem_noc MASTER_APPSS_PROC &config_noc SLAVE_QUP_1>,
					<&aggre1_noc MASTER_QUP_1 &mc_virt SLAVE_EBI1>;
			pinctrl-names = "default", "sleep";
			pinctrl-0 = <&qupv3_se14_i2c_sda_active>, <&qupv3_se14_i2c_scl_active>;
			pinctrl-1 = <&qupv3_se14_i2c_sleep>;
			dmas = <&gpi_dma1 0 6 3 64 0>,
			       <&gpi_dma1 1 6 3 64 0>;
			dma-names = "tx", "rx";
			status = "disabled";
		};

		qupv3_se14_spi: spi@a98000 {
			compatible = "qcom,spi-geni";
			reg = <0x0 0xa98000 0x0 0x4000>;
			reg-names = "se_phys";
			interrupts = <GIC_SPI 806 IRQ_TYPE_LEVEL_HIGH>;
			clock-names = "se-clk";
			clocks = <&gcc GCC_QUPV3_WRAP1_S6_CLK>;
			interconnect-names = "qup-core", "qup-config", "qup-memory";
			interconnects = <&clk_virt MASTER_QUP_CORE_1 &clk_virt SLAVE_QUP_CORE_1>,
					<&gem_noc MASTER_APPSS_PROC &config_noc SLAVE_QUP_1>,
					<&aggre1_noc MASTER_QUP_1 &mc_virt SLAVE_EBI1>;
			pinctrl-names = "default", "sleep";
			pinctrl-0 = <&qupv3_se14_spi_mosi_active>, <&qupv3_se14_spi_miso_active>,
				    <&qupv3_se14_spi_clk_active>, <&qupv3_se14_spi_cs_active>;
			pinctrl-1 = <&qupv3_se14_spi_sleep>;
			dmas = <&gpi_dma1 0 6 1 64 0>,
			       <&gpi_dma1 1 6 1 64 0>;
			dma-names = "tx", "rx";
			spi-max-frequency = <50000000>;
			status = "disabled";
		};

		qupv3_se15_i2c: i2c@a9c000 {
			compatible = "qcom,i2c-geni";
			reg = <0x0 0xa9c000 0x0 0x4000>;
			interrupts = <GIC_SPI 807 IRQ_TYPE_LEVEL_HIGH>;
			clock-names = "se-clk";
			clocks = <&gcc GCC_QUPV3_WRAP1_S7_CLK>;
			interconnect-names = "qup-core", "qup-config", "qup-memory";
			interconnects = <&clk_virt MASTER_QUP_CORE_1 &clk_virt SLAVE_QUP_CORE_1>,
					<&gem_noc MASTER_APPSS_PROC &config_noc SLAVE_QUP_1>,
					<&aggre1_noc MASTER_QUP_1 &mc_virt SLAVE_EBI1>;
			pinctrl-names = "default", "sleep";
			pinctrl-0 = <&qupv3_se15_i2c_sda_active>, <&qupv3_se15_i2c_scl_active>;
			pinctrl-1 = <&qupv3_se15_i2c_sleep>;
			dmas = <&gpi_dma1 0 7 3 64 0>,
			       <&gpi_dma1 1 7 3 64 0>;
			dma-names = "tx", "rx";
			status = "disabled";
		};

		qupv3_se15_spi: spi@a9c000 {
			compatible = "qcom,spi-geni";
			reg = <0x0 0xa9c000 0x0 0x4000>;
			reg-names = "se_phys";
			interrupts = <GIC_SPI 807 IRQ_TYPE_LEVEL_HIGH>;
			clock-names = "se-clk";
			clocks = <&gcc GCC_QUPV3_WRAP1_S7_CLK>;
			interconnect-names = "qup-core", "qup-config", "qup-memory";
			interconnects = <&clk_virt MASTER_QUP_CORE_1 &clk_virt SLAVE_QUP_CORE_1>,
					<&gem_noc MASTER_APPSS_PROC &config_noc SLAVE_QUP_1>,
					<&aggre1_noc MASTER_QUP_1 &mc_virt SLAVE_EBI1>;
			pinctrl-names = "default", "sleep";
			pinctrl-0 = <&qupv3_se15_spi_mosi_active>, <&qupv3_se15_spi_miso_active>,
				    <&qupv3_se15_spi_clk_active>, <&qupv3_se15_spi_cs_active>;
			pinctrl-1 = <&qupv3_se15_spi_sleep>;
			dmas = <&gpi_dma1 0 7 1 64 0>,
			       <&gpi_dma1 1 7 1 64 0>;
			dma-names = "tx", "rx";
			spi-max-frequency = <50000000>;
			status = "disabled";
		};
	};

	qup2_gpi_iommu_region: qup2_gpi_iommu_region {
		iommu-addresses = <&gpi_dma2 0x0 0x0 0x0 0x100000>,
				  <&gpi_dma2 0x0 0x200000 0xffffffff 0xffe00000>;
	};

	gpi_dma2: qcom,gpi-dma@800000 {
		compatible = "qcom,gpi-dma";
		#dma-cells = <5>;
		reg = <0x0 0x800000 0x0 0x60000>;
		reg-names = "gpi-top";
		iommus = <&apps_smmu 0x0436 0x0>;
		qcom,max-num-gpii = <12>;
		interrupts = <GIC_SPI 788 IRQ_TYPE_LEVEL_HIGH>,
			     <GIC_SPI 789 IRQ_TYPE_LEVEL_HIGH>,
			     <GIC_SPI 790 IRQ_TYPE_LEVEL_HIGH>,
			     <GIC_SPI 791 IRQ_TYPE_LEVEL_HIGH>,
			     <GIC_SPI 792 IRQ_TYPE_LEVEL_HIGH>,
			     <GIC_SPI 793 IRQ_TYPE_LEVEL_HIGH>,
			     <GIC_SPI 794 IRQ_TYPE_LEVEL_HIGH>,
			     <GIC_SPI 795 IRQ_TYPE_LEVEL_HIGH>,
			     <GIC_SPI 796 IRQ_TYPE_LEVEL_HIGH>,
			     <GIC_SPI 797 IRQ_TYPE_LEVEL_HIGH>,
			     <GIC_SPI 798 IRQ_TYPE_LEVEL_HIGH>,
			     <GIC_SPI 799 IRQ_TYPE_LEVEL_HIGH>;
		qcom,gpii-mask = <0x3f>;
		qcom,ev-factor = <1>;
		memory-region = <&qup2_gpi_iommu_region>;
		qcom,gpi-ee-offset = <0x10000>;
		dma-coherent;
		status = "okay";
	};

	qup2_se_iommu_region: qup2_se_iommu_region {
		iommu-addresses = <&qupv3_id_2 0x0 0x0 0x0 0x40000000>,
				  <&qupv3_id_2 0x0 0x50000000 0xffffffff 0xb0000000>;
	};

	qupv3_id_2: qcom,qupv3_2_geni_se@8c0000 {
		compatible = "qcom,geni-se-qup";
		reg = <0x0 0x8c0000 0x0 0x2000>;
		clock-names = "m-ahb", "s-ahb";
		clocks = <&gcc GCC_QUPV3_WRAP_2_M_AHB_CLK>,
			 <&gcc GCC_QUPV3_WRAP_2_S_AHB_CLK>;
		iommus = <&apps_smmu 0x0423 0x0>;
		memory-region = <&qup2_se_iommu_region>;
		qcom,iommu-geometry = <0x0 0x40000000 0x0 0x10000000>;
		qcom,iommu-dma = "fastmap";
		dma-coherent;
		#address-cells = <2>;
		#size-cells = <2>;
		ranges;
		status = "okay";

		qupv3_se16_i2c: i2c@880000 {
			compatible = "qcom,i2c-geni";
			reg = <0x0 0x880000 0x0 0x4000>;
			interrupts = <GIC_SPI 808 IRQ_TYPE_LEVEL_HIGH>;
			clock-names = "se-clk";
			clocks = <&gcc GCC_QUPV3_WRAP2_S0_CLK>;
			interconnect-names = "qup-core", "qup-config", "qup-memory";
			interconnects = <&clk_virt MASTER_QUP_CORE_2 &clk_virt SLAVE_QUP_CORE_2>,
					<&gem_noc MASTER_APPSS_PROC &config_noc SLAVE_QUP_2>,
					<&aggre1_noc MASTER_QUP_2 &mc_virt SLAVE_EBI1>;
			pinctrl-names = "default", "sleep";
			pinctrl-0 = <&qupv3_se16_i2c_sda_active>, <&qupv3_se16_i2c_scl_active>;
			pinctrl-1 = <&qupv3_se16_i2c_sleep>;
			dmas = <&gpi_dma2 0 0 3 64 0>,
			       <&gpi_dma2 1 0 3 64 0>;
			dma-names = "tx", "rx";
			status = "disabled";
		};

		qupv3_se16_spi: spi@880000 {
			compatible = "qcom,spi-geni";
			reg = <0x0 0x880000 0x0 0x4000>;
			reg-names = "se_phys";
			interrupts = <GIC_SPI 808 IRQ_TYPE_LEVEL_HIGH>;
			clock-names = "se-clk";
			clocks = <&gcc GCC_QUPV3_WRAP2_S0_CLK>;
			interconnect-names = "qup-core", "qup-config", "qup-memory";
			interconnects = <&clk_virt MASTER_QUP_CORE_2 &clk_virt SLAVE_QUP_CORE_2>,
					<&gem_noc MASTER_APPSS_PROC &config_noc SLAVE_QUP_2>,
					<&aggre1_noc MASTER_QUP_2 &mc_virt SLAVE_EBI1>;
			pinctrl-names = "default", "sleep";
			pinctrl-0 = <&qupv3_se16_spi_mosi_active>, <&qupv3_se16_spi_miso_active>,
				    <&qupv3_se16_spi_clk_active>, <&qupv3_se16_spi_cs_active>;
			pinctrl-1 = <&qupv3_se16_spi_sleep>;
			dmas = <&gpi_dma2 0 0 1 64 0>,
			       <&gpi_dma2 1 0 1 64 0>;
			dma-names = "tx", "rx";
			spi-max-frequency = <50000000>;
			status = "disabled";
		};

		qupv3_se17_i2c: i2c@884000 {
			compatible = "qcom,i2c-geni";
			reg = <0x0 0x884000 0x0 0x4000>;
			interrupts = <GIC_SPI 809 IRQ_TYPE_LEVEL_HIGH>;
			clock-names = "se-clk";
			clocks = <&gcc GCC_QUPV3_WRAP2_S1_CLK>;
			interconnect-names = "qup-core", "qup-config", "qup-memory";
			interconnects = <&clk_virt MASTER_QUP_CORE_2 &clk_virt SLAVE_QUP_CORE_2>,
					<&gem_noc MASTER_APPSS_PROC &config_noc SLAVE_QUP_2>,
					<&aggre1_noc MASTER_QUP_2 &mc_virt SLAVE_EBI1>;
			pinctrl-names = "default", "sleep";
			pinctrl-0 = <&qupv3_se17_i2c_sda_active>, <&qupv3_se17_i2c_scl_active>;
			pinctrl-1 = <&qupv3_se17_i2c_sleep>;
			dmas = <&gpi_dma2 0 1 3 64 0>,
			       <&gpi_dma2 1 1 3 64 0>;
			dma-names = "tx", "rx";
			status = "disabled";
		};

		qupv3_se17_spi: spi@884000 {
			compatible = "qcom,spi-geni";
			reg = <0x0 0x884000 0x0 0x4000>;
			reg-names = "se_phys";
			interrupts = <GIC_SPI 809 IRQ_TYPE_LEVEL_HIGH>;
			clock-names = "se-clk";
			clocks = <&gcc GCC_QUPV3_WRAP2_S1_CLK>;
			interconnect-names = "qup-core", "qup-config", "qup-memory";
			interconnects = <&clk_virt MASTER_QUP_CORE_2 &clk_virt SLAVE_QUP_CORE_2>,
					<&gem_noc MASTER_APPSS_PROC &config_noc SLAVE_QUP_2>,
					<&aggre1_noc MASTER_QUP_2 &mc_virt SLAVE_EBI1>;
			pinctrl-names = "default", "sleep";
			pinctrl-0 = <&qupv3_se17_spi_mosi_active>, <&qupv3_se17_spi_miso_active>,
				    <&qupv3_se17_spi_clk_active>, <&qupv3_se17_spi_cs_active>;
			pinctrl-1 = <&qupv3_se17_spi_sleep>;
			dmas = <&gpi_dma2 0 1 1 64 0>,
			       <&gpi_dma2 1 1 1 64 0>;
			dma-names = "tx", "rx";
			spi-max-frequency = <50000000>;
			status = "disabled";
		};

		qupv3_se18_i2c: i2c@888000 {
			compatible = "qcom,i2c-geni";
			reg = <0x0 0x888000 0x0 0x4000>;
			interrupts = <GIC_SPI 810 IRQ_TYPE_LEVEL_HIGH>;
			clock-names = "se-clk";
			clocks = <&gcc GCC_QUPV3_WRAP2_S2_CLK>;
			interconnect-names = "qup-core", "qup-config", "qup-memory";
			interconnects = <&clk_virt MASTER_QUP_CORE_2 &clk_virt SLAVE_QUP_CORE_2>,
					<&gem_noc MASTER_APPSS_PROC &config_noc SLAVE_QUP_2>,
					<&aggre1_noc MASTER_QUP_2 &mc_virt SLAVE_EBI1>;
			pinctrl-names = "default", "sleep";
			pinctrl-0 = <&qupv3_se18_i2c_sda_active>, <&qupv3_se18_i2c_scl_active>;
			pinctrl-1 = <&qupv3_se18_i2c_sleep>;
			dmas = <&gpi_dma2 0 2 3 64 0>,
			       <&gpi_dma2 1 2 3 64 0>;
			dma-names = "tx", "rx";
			status = "disabled";
		};

		qupv3_se18_spi: spi@888000 {
			compatible = "qcom,spi-geni";
			reg = <0x0 0x888000 0x0 0x4000>;
			reg-names = "se_phys";
			interrupts = <GIC_SPI 810 IRQ_TYPE_LEVEL_HIGH>;
			clock-names = "se-clk";
			clocks = <&gcc GCC_QUPV3_WRAP2_S2_CLK>;
			interconnect-names = "qup-core", "qup-config", "qup-memory";
			interconnects = <&clk_virt MASTER_QUP_CORE_2 &clk_virt SLAVE_QUP_CORE_2>,
					<&gem_noc MASTER_APPSS_PROC &config_noc SLAVE_QUP_2>,
					<&aggre1_noc MASTER_QUP_2 &mc_virt SLAVE_EBI1>;
			pinctrl-names = "default", "sleep";
			pinctrl-0 = <&qupv3_se18_spi_mosi_active>, <&qupv3_se18_spi_miso_active>,
				    <&qupv3_se18_spi_clk_active>, <&qupv3_se18_spi_cs_active>;
			pinctrl-1 = <&qupv3_se18_spi_sleep>;
			dmas = <&gpi_dma2 0 2 1 64 0>,
			       <&gpi_dma2 1 2 1 64 0>;
			dma-names = "tx", "rx";
			spi-max-frequency = <50000000>;
			status = "disabled";
		};

		qupv3_se19_i2c: i2c@88c000 {
			compatible = "qcom,i2c-geni";
			reg = <0x0 0x88c000 0x0 0x4000>;
			interrupts = <GIC_SPI 811 IRQ_TYPE_LEVEL_HIGH>;
			clock-names = "se-clk";
			clocks = <&gcc GCC_QUPV3_WRAP2_S3_CLK>;
			interconnect-names = "qup-core", "qup-config", "qup-memory";
			interconnects = <&clk_virt MASTER_QUP_CORE_2 &clk_virt SLAVE_QUP_CORE_2>,
					<&gem_noc MASTER_APPSS_PROC &config_noc SLAVE_QUP_2>,
					<&aggre1_noc MASTER_QUP_2 &mc_virt SLAVE_EBI1>;
			pinctrl-names = "default", "sleep";
			pinctrl-0 = <&qupv3_se19_i2c_sda_active>, <&qupv3_se19_i2c_scl_active>;
			pinctrl-1 = <&qupv3_se19_i2c_sleep>;
			dmas = <&gpi_dma2 0 3 3 64 0>,
			       <&gpi_dma2 1 3 3 64 0>;
			dma-names = "tx", "rx";
			status = "disabled";
		};

		qupv3_se19_spi: spi@88c000 {
			compatible = "qcom,spi-geni";
			reg = <0x0 0x88c000 0x0 0x4000>;
			reg-names = "se_phys";
			interrupts = <GIC_SPI 811 IRQ_TYPE_LEVEL_HIGH>;
			clock-names = "se-clk";
			clocks = <&gcc GCC_QUPV3_WRAP2_S3_CLK>;
			interconnect-names = "qup-core", "qup-config", "qup-memory";
			interconnects = <&clk_virt MASTER_QUP_CORE_2 &clk_virt SLAVE_QUP_CORE_2>,
					<&gem_noc MASTER_APPSS_PROC &config_noc SLAVE_QUP_2>,
					<&aggre1_noc MASTER_QUP_2 &mc_virt SLAVE_EBI1>;
			pinctrl-names = "default", "sleep";
			pinctrl-0 = <&qupv3_se19_spi_mosi_active>, <&qupv3_se19_spi_miso_active>,
				    <&qupv3_se19_spi_clk_active>, <&qupv3_se19_spi_cs_active>;
			pinctrl-1 = <&qupv3_se19_spi_sleep>;
			dmas = <&gpi_dma2 0 3 1 64 0>,
			       <&gpi_dma2 1 3 1 64 0>;
			dma-names = "tx", "rx";
			spi-max-frequency = <50000000>;
			status = "disabled";
		};

		qupv3_se20_i2c: i2c@890000 {
			compatible = "qcom,i2c-geni";
			reg = <0x0 0x890000 0x0 0x4000>;
			interrupts = <GIC_SPI 812 IRQ_TYPE_LEVEL_HIGH>;
			clock-names = "se-clk";
			clocks = <&gcc GCC_QUPV3_WRAP2_S4_CLK>;
			interconnect-names = "qup-core", "qup-config", "qup-memory";
			interconnects = <&clk_virt MASTER_QUP_CORE_2 &clk_virt SLAVE_QUP_CORE_2>,
					<&gem_noc MASTER_APPSS_PROC &config_noc SLAVE_QUP_2>,
					<&aggre1_noc MASTER_QUP_2 &mc_virt SLAVE_EBI1>;
			pinctrl-names = "default", "sleep";
			pinctrl-0 = <&qupv3_se20_i2c_sda_active>, <&qupv3_se20_i2c_scl_active>;
			pinctrl-1 = <&qupv3_se20_i2c_sleep>;
			dmas = <&gpi_dma2 0 4 3 64 0>,
			       <&gpi_dma2 1 4 3 64 0>;
			dma-names = "tx", "rx";
			status = "disabled";
		};

		qupv3_se20_spi: spi@890000 {
			compatible = "qcom,spi-geni";
			reg = <0x0 0x890000 0x0 0x4000>;
			reg-names = "se_phys";
			interrupts = <GIC_SPI 812 IRQ_TYPE_LEVEL_HIGH>;
			clock-names = "se-clk";
			clocks = <&gcc GCC_QUPV3_WRAP2_S4_CLK>;
			interconnect-names = "qup-core", "qup-config", "qup-memory";
			interconnects = <&clk_virt MASTER_QUP_CORE_2 &clk_virt SLAVE_QUP_CORE_2>,
					<&gem_noc MASTER_APPSS_PROC &config_noc SLAVE_QUP_2>,
					<&aggre1_noc MASTER_QUP_2 &mc_virt SLAVE_EBI1>;
			pinctrl-names = "default", "sleep";
			pinctrl-0 = <&qupv3_se20_spi_mosi_active>, <&qupv3_se20_spi_miso_active>,
				    <&qupv3_se20_spi_clk_active>, <&qupv3_se20_spi_cs_active>;
			pinctrl-1 = <&qupv3_se20_spi_sleep>;
			dmas = <&gpi_dma2 0 4 1 64 0>,
			       <&gpi_dma2 1 4 1 64 0>;
			dma-names = "tx", "rx";
			spi-max-frequency = <50000000>;
			status = "disabled";
		};

		qupv3_se21_2uart: qcom,qup_uart@894000 {
			compatible = "qcom,geni-debug-uart";
			reg = <0x0 0x894000 0x0 0x4000>;
			reg-names = "se_phys";
			interrupts = <GIC_SPI 813 IRQ_TYPE_LEVEL_HIGH>;
			clock-names = "se";
			clocks = <&gcc GCC_QUPV3_WRAP2_S5_CLK>;
			interconnect-names = "qup-core", "qup-config";
			interconnects = <&clk_virt MASTER_QUP_CORE_2 &clk_virt SLAVE_QUP_CORE_2>,
					<&gem_noc MASTER_APPSS_PROC &config_noc SLAVE_QUP_2>;
			pinctrl-names = "default", "sleep";
			pinctrl-0 = <&qupv3_se21_2uart_active>;
			pinctrl-1 = <&qupv3_se21_2uart_sleep>;
			status = "disabled";
		};

		qupv3_se22_i2c: i2c@898000 {
			compatible = "qcom,i2c-geni";
			reg = <0x0 0x898000 0x0 0x4000>;
			interrupts = <GIC_SPI 814 IRQ_TYPE_LEVEL_HIGH>;
			clock-names = "se-clk";
			clocks = <&gcc GCC_QUPV3_WRAP2_S6_CLK>;
			interconnect-names = "qup-core", "qup-config", "qup-memory";
			interconnects = <&clk_virt MASTER_QUP_CORE_2 &clk_virt SLAVE_QUP_CORE_2>,
					<&gem_noc MASTER_APPSS_PROC &config_noc SLAVE_QUP_2>,
					<&aggre1_noc MASTER_QUP_2 &mc_virt SLAVE_EBI1>;
			pinctrl-names = "default", "sleep";
			pinctrl-0 = <&qupv3_se22_i2c_sda_active>, <&qupv3_se22_i2c_scl_active>;
			pinctrl-1 = <&qupv3_se22_i2c_sleep>;
			dmas = <&gpi_dma2 0 6 3 64 0>,
			       <&gpi_dma2 1 6 3 64 0>;
			dma-names = "tx", "rx";
			status = "disabled";
		};

		qupv3_se22_spi: spi@898000 {
			compatible = "qcom,spi-geni";
			reg = <0x0 0x898000 0x0 0x4000>;
			reg-names = "se_phys";
			interrupts = <GIC_SPI 814 IRQ_TYPE_LEVEL_HIGH>;
			clock-names = "se-clk";
			clocks = <&gcc GCC_QUPV3_WRAP2_S6_CLK>;
			interconnect-names = "qup-core", "qup-config", "qup-memory";
			interconnects = <&clk_virt MASTER_QUP_CORE_2 &clk_virt SLAVE_QUP_CORE_2>,
					<&gem_noc MASTER_APPSS_PROC &config_noc SLAVE_QUP_2>,
					<&aggre1_noc MASTER_QUP_2 &mc_virt SLAVE_EBI1>;
			pinctrl-names = "default", "sleep";
			pinctrl-0 = <&qupv3_se22_spi_mosi_active>, <&qupv3_se22_spi_miso_active>,
				    <&qupv3_se22_spi_clk_active>, <&qupv3_se22_spi_cs_active>;
			pinctrl-1 = <&qupv3_se22_spi_sleep>;
			dmas = <&gpi_dma2 0 6 1 64 0>,
			       <&gpi_dma2 1 6 1 64 0>;
			dma-names = "tx", "rx";
			spi-max-frequency = <50000000>;
			status = "disabled";
		};

		qupv3_se23_i2c: i2c@89c000 {
			compatible = "qcom,i2c-geni";
			reg = <0x0 0x89c000 0x0 0x4000>;
			interrupts = <GIC_SPI 815 IRQ_TYPE_LEVEL_HIGH>;
			clock-names = "se-clk";
			clocks = <&gcc GCC_QUPV3_WRAP2_S7_CLK>;
			interconnect-names = "qup-core", "qup-config", "qup-memory";
			interconnects = <&clk_virt MASTER_QUP_CORE_2 &clk_virt SLAVE_QUP_CORE_2>,
					<&gem_noc MASTER_APPSS_PROC &config_noc SLAVE_QUP_2>,
					<&aggre1_noc MASTER_QUP_2 &mc_virt SLAVE_EBI1>;
			pinctrl-names = "default", "sleep";
			pinctrl-0 = <&qupv3_se23_i2c_sda_active>, <&qupv3_se23_i2c_scl_active>;
			pinctrl-1 = <&qupv3_se23_i2c_sleep>;
			dmas = <&gpi_dma2 0 7 3 64 0>,
			       <&gpi_dma2 1 7 3 64 0>;
			dma-names = "tx", "rx";
			status = "disabled";
		};

		qupv3_se23_spi: spi@89c000 {
			compatible = "qcom,spi-geni";
			reg = <0x0 0x89c000 0x0 0x4000>;
			reg-names = "se_phys";
			interrupts = <GIC_SPI 815 IRQ_TYPE_LEVEL_HIGH>;
			clock-names = "se-clk";
			clocks = <&gcc GCC_QUPV3_WRAP2_S7_CLK>;
			interconnect-names = "qup-core", "qup-config", "qup-memory";
			interconnects = <&clk_virt MASTER_QUP_CORE_2 &clk_virt SLAVE_QUP_CORE_2>,
					<&gem_noc MASTER_APPSS_PROC &config_noc SLAVE_QUP_2>,
					<&aggre1_noc MASTER_QUP_2 &mc_virt SLAVE_EBI1>;
			pinctrl-names = "default", "sleep";
			pinctrl-0 = <&qupv3_se23_spi_mosi_active>, <&qupv3_se23_spi_miso_active>,
				    <&qupv3_se23_spi_clk_active>, <&qupv3_se23_spi_cs_active>;
			pinctrl-1 = <&qupv3_se23_spi_sleep>;
			dmas = <&gpi_dma2 0 7 1 64 0>,
			       <&gpi_dma2 1 7 1 64 0>;
			dma-names = "tx", "rx";
			spi-max-frequency = <50000000>;
			status = "disabled";
		};
	};
};
